VERSION ""

NS_ :

BS_:

BU_: CHASSIS
VAL_TABLE_ PRND 251 "P" 126 "D" 125 "N" 124 "R" ;

BO_ 2565866755 PRND: 8 Vector__XXX
 SG_ GEAR_Status : 0|8@1+ (1,0) [0|0] ""  CHASSIS

BO_ 2365579776 APS2: 8 Vector__XXX
 SG_ AccelPedal : 48|8@1+ (0.3906,0) [0|99.603] ""  CHASSIS

BO_ 2364539648 APS: 8 Vector__XXX
 SG_ AP_Status2 : 6|2@1+ (1,0) [0|3] ""  CHASSIS
 SG_ AP_Status1 : 0|2@1+ (1,0) [0|3] ""  CHASSIS

BO_ 2566878987 BRK: 8 Vector__XXX
 SG_ MC_Pres : 16|12@1+ (0.1,0) [0|409.5] "bar"  CHASSIS

BO_ 2565865739 DRV_BRK: 8 Vector__XXX
 SG_ Brk_idx : 6|2@1+ (1,0) [0|3] ""  CHASSIS

BO_ 2364539904 EGS: 8 Vector__XXX
 SG_ Engine_RPM : 24|16@1+ (0.125,0) [0|8191.875] "rpm"  CHASSIS

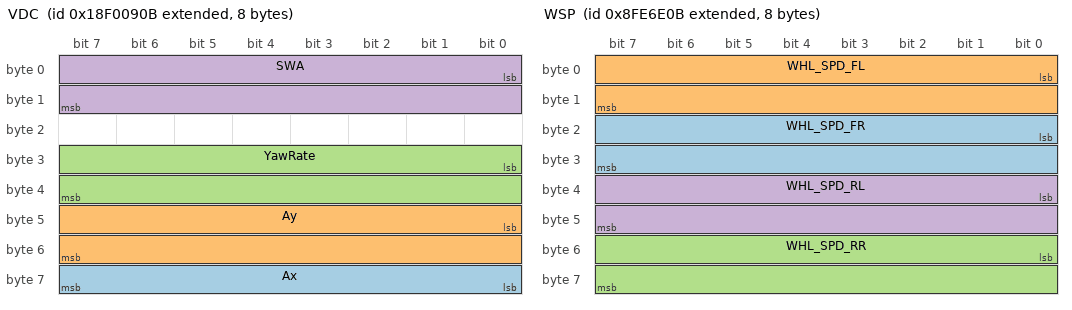
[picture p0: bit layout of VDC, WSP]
BO_ 2565867787 VDC: 8 Vector__XXX
 SG_ Ax : 56|8@1+ (0.1,-12.5) [-12.5|13] "m/s^2"  CHASSIS
 SG_ Ay : 40|16@1+ (0.000488,-15.687) [-15.687|16.29408] "m/s^2"  CHASSIS
 SG_ YawRate : 24|16@1+ (0.000122,-3.92) [-3.92|4.07527] "rad/s"  CHASSIS
 SG_ SWA : 0|16@1+ (0.000977,-31.374) [-31.374|32.653695] "rad"  CHASSIS

BO_ 2298375691 WSP: 8 Vector__XXX
 SG_ WHL_SPD_FR : 16|16@1+ (0.003906,0) [0|255.97971] "kph"  CHASSIS
 SG_ WHL_SPD_FL : 0|16@1+ (0.003906,0) [0|255.97971] "kph"  CHASSIS
 SG_ WHL_SPD_RR : 48|16@1+ (0.003906,0) [0|255.97971] "kph"  CHASSIS
 SG_ WHL_SPD_RL : 32|16@1+ (0.003906,0) [0|255.97971] "kph"  CHASSIS

BO_ 2566865175 VEH_SPD: 8 Vector__XXX
 SG_ Vx : 8|9@1+ (0.5,0) [0|255.5] "kph"  CHASSIS

BO_ 2566852638 CLU: 8 Vector__XXX
 SG_ Right_TurnSig : 30|2@1+ (1,0) [0|3] ""  CHASSIS
 SG_ Left_TurnSig : 28|2@1+ (1,0) [0|3] ""  CHASSIS

CM_ SG_ 2565866755 GEAR_Status "
P : 251d
R : 124d
N : 125d
D : 126d";
CM_ SG_ 2364539648 AP_Status2 "0 : Low Idel Condition X
1 : Low Idel Condition O
2 : Error

3 : N/A";
CM_ SG_ 2364539648 AP_Status1 "0 : Low Idel Condition X
1 : Low Idel Condition O
2 : Error

3 : N/A";
CM_ SG_ 2565865739 Brk_idx "0 : BRAKE Release 
1 : BRAKE ON";
CM_ BO_ 2565867787 "Steer Angle";
CM_ SG_ 2565867787 Ax "Longitudinal_Acceleration_Signal";
CM_ SG_ 2565867787 Ay "Lateral Acceleation";
CM_ SG_ 2565867787 YawRate "YawRate";
CM_ SG_ 2565867787 SWA "Steer Angle Signal";
CM_ BO_ 2298375691 "Wheel Speed";
CM_ SG_ 2298375691 WHL_SPD_FR "Front Right Wheel Speed";
CM_ SG_ 2298375691 WHL_SPD_FL "Front Left Wheel Speed";
CM_ SG_ 2298375691 WHL_SPD_RR "Rear Right Wheel Speed Signal";
CM_ SG_ 2298375691 WHL_SPD_RL "Rear Left Wheel Speed Signal";
CM_ BO_ 2566865175 "Vehicle Speed";
CM_ SG_ 2566865175 Vx "Vehicle Speed 
0~180Km";
CM_ BO_ 2566852638 "Turn Singal";
CM_ SG_ 2566852638 Right_TurnSig "Right Turn Signal
0x0 : off
ox1 : on";
CM_ SG_ 2566852638 Left_TurnSig "Left Turn Signal
0x0 : off
0x1 : on";
BA_DEF_ SG_  "GenSigSendType" ENUM  "Cyclic","OnWrite","OnWriteWithRepetition","OnChange","OnChangeWithRepetition","IfActive","IfActiveWithRepetition","NoSigSendType";
BA_DEF_ BO_  "GenMsgSendType" ENUM  "Cyclic","not_used","not_used","not_used","not_used","Cyclic","not_used","IfActive","NoMsgSendType";
BA_DEF_  "DBName" STRING ;
BA_DEF_  "BusType" STRING ;
BA_DEF_DEF_  "GenSigSendType" "Cyclic";
BA_DEF_DEF_  "GenMsgSendType" "NoMsgSendType";
BA_DEF_DEF_  "DBName" "";
BA_DEF_DEF_  "BusType" "CAN";
BA_ "DBName" "SOLATI";
VAL_ 2565866755 GEAR_Status 251 "P" 126 "D" 125 "N" 124 "R" ;
